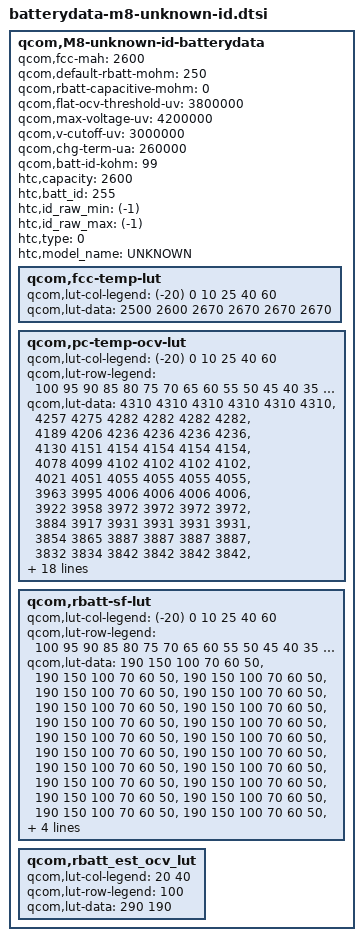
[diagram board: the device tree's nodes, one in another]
	qcom,M8-unknown-id-batterydata {
	qcom,fcc-mah = <2600>;
	qcom,default-rbatt-mohm = <250>;
	qcom,rbatt-capacitive-mohm = <0>;
	qcom,flat-ocv-threshold-uv = <3800000>;
	qcom,max-voltage-uv = <4200000>;
	qcom,v-cutoff-uv = <3000000>;
	qcom,chg-term-ua = <260000>;
	qcom,batt-id-kohm = <99>;
	htc,capacity = <2600>;
	htc,batt_id = <255>;
	htc,id_raw_min = <(-1)>;
	htc,id_raw_max = <(-1)>;
	htc,type = <0>;
	htc,model_name = "UNKNOWN";

	qcom,fcc-temp-lut {
		qcom,lut-col-legend = <(-20) 0 10 25 40 60>;
		qcom,lut-data = <2500 2600 2670 2670 2670 2670>;
	};

	qcom,pc-temp-ocv-lut {
		qcom,lut-col-legend = <(-20) 0 10 25 40 60>;
		qcom,lut-row-legend = <100 95 90 85 80 75 70 65 60 55 50 45 40 35 30 25 20 15 10 9 8 7 6 5 4 3 2 1 0>;
		qcom,lut-data = <4310 4310 4310 4310 4310 4310>,
				<4257 4275 4282 4282 4282 4282>,
				<4189 4206 4236 4236 4236 4236>,
				<4130 4151 4154 4154 4154 4154>,
				<4078 4099 4102 4102 4102 4102>,
				<4021 4051 4055 4055 4055 4055>,
				<3963 3995 4006 4006 4006 4006>,
				<3922 3958 3972 3972 3972 3972>,
				<3884 3917 3931 3931 3931 3931>,
				<3854 3865 3887 3887 3887 3887>,
				<3832 3834 3842 3842 3842 3842>,
				<3817 3817 3820 3820 3820 3820>,
				<3806 3802 3802 3802 3802 3802>,
				<3796 3789 3790 3790 3790 3790>,
				<3786 3780 3776 3776 3776 3776>,
				<3773 3770 3755 3755 3755 3755>,
				<3757 3751 3730 3730 3730 3730>,
				<3739 3711 3694 3694 3694 3694>,
				<3714 3693 3686 3686 3686 3686>,
				<3707 3678 3680 3680 3680 3680>,
				<3700 3664 3660 3660 3660 3660>,
				<3692 3650 3649 3649 3649 3649>,
				<3685 3636 3638 3638 3638 3638>,
				<3678 3626 3627 3627 3627 3627>,
				<3624 3538 3490 3490 3490 3490>,
				<3571 3453 3425 3425 3425 3425>,
				<3518 3368 3275 3275 3275 3245>,
				<3465 3283 3117 3117 3117 3117>,
				<3411 3198 3000 3000 3000 3000>;
	};

	qcom,rbatt-sf-lut {
		qcom,lut-col-legend = <(-20) 0 10 25 40 60>;
		qcom,lut-row-legend = <100 95 90 85 80 75 70 65 60 55 50 45 40 35 30 25 20 15 10 9 8 7 6 5 4 3 2 1>;
		qcom,lut-data = <190 150 100 70 60 50>,
				<190 150 100 70 60 50>,
				<190 150 100 70 60 50>,
				<190 150 100 70 60 50>,
				<190 150 100 70 60 50>,
				<190 150 100 70 60 50>,
				<190 150 100 70 60 50>,
				<190 150 100 70 60 50>,
				<190 150 100 70 60 50>,
				<190 150 100 70 60 50>,
				<190 150 100 70 60 50>,
				<190 150 100 70 60 50>,
				<190 150 100 70 60 50>,
				<190 150 100 70 60 50>,
				<190 150 100 70 60 50>,
				<190 150 100 70 60 50>,
				<190 150 100 70 60 50>,
				<190 150 100 70 60 50>,
				<190 150 100 70 60 50>,
				<190 150 100 70 60 50>,
				<190 150 100 70 60 50>,
				<190 150 100 70 60 50>,
				<190 150 100 70 60 50>,
				<190 150 100 70 60 50>,
				<190 150 100 70 60 50>,
				<190 150 100 70 60 50>,
				<190 150 100 70 60 50>,
				<190 150 100 70 60 50>;
		};

	qcom,rbatt_est_ocv_lut {
		qcom,lut-col-legend = <20 40>;
		qcom,lut-row-legend = <100>;
		qcom,lut-data = <290 190>;
		};
	};
